AUTOSAR XML (schema 00050)
package /Pkg_ErrorMgrAgg_1_0_B/ComponentTypes
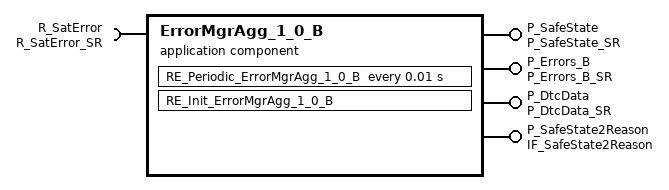
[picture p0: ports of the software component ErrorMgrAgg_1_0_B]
  application sw component type ErrorMgrAgg_1_0_B
    provide port P_SafeState: nonqueued-sender-com-spec{data-element=SafeStateOp, init-value=constant-reference=init_SafeStateOp}, provided-interface=P_SafeState_SR
    provide port P_Errors_B: nonqueued-sender-com-spec=Errors_B, provided-interface=P_Errors_B_SR
    require port R_SatError: required-interface=R_SatError_SR
      required-com-specs:
        data-element=Data_ErrorMgr_ErrorCommPack_1_0_B, init-value=constant-reference=init_Data_ErrorMgr_ErrorCommPack_1_0_B
        data-element=Data_ErrorMgr_ErrorCommPack_2_0_B, init-value=constant-reference=init_Data_ErrorMgr_ErrorCommPack_2_0_B
        data-element=Data_ErrorMgr_ErrorCommPack_2_1_B, init-value=constant-reference=init_Data_ErrorMgr_ErrorCommPack_2_1_B
        data-element=Data_ErrorMgr_ErrorCommPack_QNX_B, init-value=constant-reference=init_Data_ErrorMgr_ErrorCommPack_QNX_B
    provide port P_DtcData: provided-interface=P_DtcData_SR
      provided-com-specs:
        data-element=Data_DtcStatus_B, init-value=constant-reference=init_Data_DtcStatus_B
        data-element=Data_DtcAddData_B, init-value=constant-reference=init_Data_DtcAddData_B
    provide port P_SafeState2Reason: nonqueued-sender-com-spec{data-element=FaultEnum_u16, init-value=0}, provided-interface=IF_SafeState2Reason
    behavior ErrorMgrAgg_1_0_B_InternalBehavior: handle-termination-and-restart=NO-SUPPORT
      timing event TMT_RE_Periodic_ErrorMgrAgg_1_0_B: start-on-event=RE_Periodic_ErrorMgrAgg_1_0_B, period=0.01
      init event InitEvent: start-on-event=RE_Init_ErrorMgrAgg_1_0_B
      port-api-options:
        enable-take-address=false, error-handling=NO-TRANSFORMER-ERROR-HANDLING, indirect-api=false, port=P_Errors_B
        enable-take-address=false, error-handling=NO-TRANSFORMER-ERROR-HANDLING, indirect-api=false, port=P_SafeState
        enable-take-address=false, error-handling=NO-TRANSFORMER-ERROR-HANDLING, indirect-api=false, port=R_SatError
        enable-take-address=false, error-handling=NO-TRANSFORMER-ERROR-HANDLING, indirect-api=false, port=P_DtcData
      runnable RE_Periodic_ErrorMgrAgg_1_0_B  # Periodic Runnable of Satellite
        data-receive-point-by-arguments:
          4 x access:
            REC_R_SatError_Data_ErrorMgr_ErrorCommPack_1_0_B: accessed-variable=R_SatError.Data_ErrorMgr_ErrorCommPack_1_0_B
            REC_R_SatError_Data_ErrorMgr_ErrorCommPack_2_0_B: accessed-variable=R_SatError.Data_ErrorMgr_ErrorCommPack_2_0_B
            REC_R_SatError_Data_ErrorMgr_ErrorCommPack_2_1_B: accessed-variable=R_SatError.Data_ErrorMgr_ErrorCommPack_2_1_B
            REC_R_SatError_Data_ErrorMgr_ErrorCommPack_QNX_B: accessed-variable=R_SatError.Data_ErrorMgr_ErrorCommPack_QNX_B
        data-send-points:
          5 x access:
            SEND_P_SafeState_SafeStateOp: accessed-variable=P_SafeState.SafeStateOp
            SEND_P_Errors_B_Errors_B: accessed-variable=P_Errors_B.Errors_B
            SEND_P_DtcData_Data_DtcStatus_B: accessed-variable=P_DtcData.Data_DtcStatus_B
            SEND_P_DtcData_Data_DtcAddData_B: accessed-variable=P_DtcData.Data_DtcAddData_B
            SEND_P_SafeState2Reason_FaultEnum_u16: accessed-variable=P_SafeState2Reason.FaultEnum_u16
      runnable RE_Init_ErrorMgrAgg_1_0_B  # Init Runnable
  swc implementation ErrorMgrAgg_1_0_B_Implementation: programming-language=C, vendor-id=0, behavior=ErrorMgrAgg_1_0_B_InternalBehavior
    code-descriptors:
      code Default: artifact-descriptors=autosar-engineering-object=category=SWSRC
